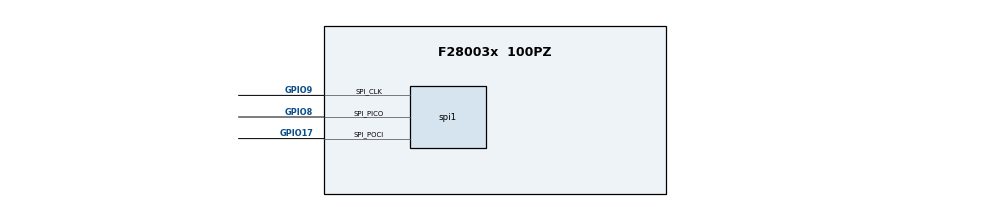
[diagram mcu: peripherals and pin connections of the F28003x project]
/**
 * @cliArgs --device "F28003x" --part "F28003x_100PZ" --package "100PZ" --context "system" --product "C2000WARE@5.03.00.00"
 * @versions {"tool":"1.21.0+3721"}
 */

/**
 * Import the modules used in this configuration.
 */
const device_support = scripting.addModule("/driverlib/device_support.js");
const spi            = scripting.addModule("/driverlib/spi.js", {}, false);
const spi1           = spi.addInstance();

/**
 * Write custom configuration values to the imported modules.
 */
spi1.dataWidth               = "8";
spi1.$name                   = "spia_encoder";
spi1.spi.$assign             = "SPIA";
spi1.spi.spi_picoPin.$assign = "GPIO8";
spi1.spi.spi_pociPin.$assign = "GPIO17";
spi1.spi.spi_clkPin.$assign  = "GPIO9";
spi1.picoQual.$name          = "myGPIOQUAL0";
spi1.pociQual.$name          = "myGPIOQUAL1";
spi1.clkQual.$name           = "myGPIOQUAL2";
spi1.pteQual.$name           = "myGPIOQUAL3";

/**
 * Pinmux solution for unlocked pins/peripherals. This ensures that minor changes to the automatic solver in a future
 * version of the tool will not impact the pinmux you originally saw.  These lines can be completely deleted in order to
 * re-solve from scratch.
 */
spi1.spi.spi_ptePin.$suggestSolution = "GPIO0";
